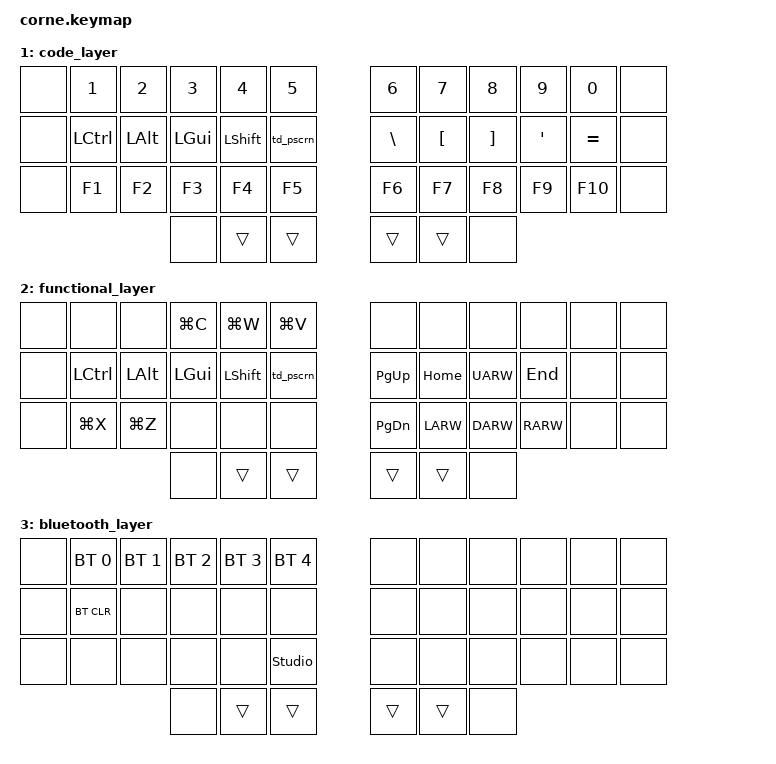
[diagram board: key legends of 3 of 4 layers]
/*
 * Copyright (c) 2020 The ZMK Contributors
 *
 * SPDX-License-Identifier: MIT
 */

#include <behaviors.dtsi>
#include <dt-bindings/zmk/keys.h>
#include <dt-bindings/zmk/bt.h>
#include <dt-bindings/zmk/ext_power.h>


/* flashing new u2f refer here https://github.com/superxc3/xcmkb/tree/main/list%20of%20items/list%20of%20keyboards/60percent/sofle/sofle%20zmk#part-b-flash-zmk
 * macro refer to this link https://github.com/superxc3/xcmkb/blob/main/list%20of%20guide/zmk-setup.md#zmk-macro
 * reserve
 * reserve
 */

// Layers
#define DEFAULT 0
#define CODE 	1
#define FUNC	2
#define BLE	3

// Bluetooth
#define BT1 	&bt BT_SEL 0
#define BT2 	&bt BT_SEL 1
#define BT3 	&bt BT_SEL 2
#define BT4 	&bt BT_SEL 3
#define BT5 	&bt BT_SEL 4

//========================================================
//===================== For MacOS ========================
//========================================================
// Home row mods macro
#define HRML(k1,k2,k3,k4) &bhm LCTRL k1	&bhm LALT k2  &bhm LGUI k3  &bhm LSHFT k4
#define HRMR(k1,k2,k3,k4) &bhm RSHFT k1	&bhm RGUI k2  &bhm RALT k3  &bhm RCTRL k4

// MacOS shortcuts 
#define GUI_X 			&kp LG(X)
#define GUI_Y 			&kp LG(Y)
#define GUI_W 			&kp LG(W)
#define GUI_K  			&kp LG(K)
#define GUI_C 			&kp LG(C)
#define GUI_V			&kp LG(V)
#define GUI_Z			&kp LG(Z)
#define PSCRN_COPY 		&kp LG(LS(LCTRL(4)))
#define PSCRN_SAVE 		&kp LG(LS(4))
#define SELECT_LEFT_WORD 	&kp LA(LS(LEFT)
#define SELECT_RIGHT_WORD	&kp LA(LS(RIGHT)

&caps_word {
	continue-list = <UNDERSCORE MINUS SPACE>;
};

/ {
	behaviors {
	        bhm: balanced_homerow_mods {
			compatible = "zmk,behavior-hold-tap";
			label = "HOMEROW_MODS";
			#binding-cells = <2>;
			tapping-term-ms = <200>;    // <---[[moderate duration]]
			quick-tap-ms = <125>;
			global-quick-tap;
			flavor = "balanced";
			bindings = <&kp>, <&kp>;
	        };

		td0: tap_dance_0 {
			compatible = "zmk,behavior-tap-dance";
			label = "TAP_DANCE_0";
			#binding-cells = <0>;
			tapping-term-ms = <500>;
			bindings = <&sk LSHFT>, <&caps_word>;
		};

		td_grv: tap_dance_grave_tilde {
			compatible = "zmk,behavior-tap-dance";
			label = "TAP_DANCE_GRAVE_TILDE";
			#binding-cells = <0>;
			tapping-term-ms = <500>;
			bindings = <&kp GRAVE>, <&kp TILDE>;
		};

		td_pscrn: tap_dance_pscrn {
			compatible = "zmk,behavior-tap-dance";
			label = "TAP_DANCE_PSCRN";
			#binding-cells = <0>;
			tapping-term-ms = <500>;
			bindings = <&kp LG(LS(LC(N4)))>, <&kp LG(LS(N4))>;
		};
    	};

	combos {
			compatible = "zmk,combos";

			combo_bluetooth {
				timeout-ms = <100>;
				key-positions = <39 40>;
				bindings = <&mo BLE>;
			};

			combo_grave {
				timeout-ms = <35>;
				key-positions = <1 2>;
				bindings = <&td_grv>;
				layers = <0>;
			};

			combo_esc {
				timeout-ms = <35>;
				key-positions = <2 3>;
				bindings = <&kp ESC>;
				layers = <0>;
			};

			combo_backspace {
				timeout-ms = <50>;
				key-positions = <14 15>;
				bindings = <&kp BSPC>;
				layers = <0>;
			};

			combo_delete {
				timeout-ms = <50>;
				key-positions = <15 16>;
				bindings = <&kp DEL>;
				layers = <0>;
			};

			combo_left_parenthesis {
				timeout-ms = <35>;
				key-positions = <7 8>;
				bindings = <&kp LPAR>;
				layers = <0>;
			};

			combo_right_parenthesis {
				timeout-ms = <35>;
				key-positions = <8 9>;
				bindings = <&kp RPAR>;
				layers = <0>;
			};

			combo_semicolon {
				timeout-ms = <35>;
				key-positions = <19 20>;
				bindings = <&kp SEMI>;
				layers = <0>;
			};

			combo_enter {
				timeout-ms = <50>;
				key-positions = <20 21>;
				bindings = <&kp ENTER>;
				layers = <0>;
			};

			combo_sk_lgui {
				timeout-ms = <50>;
				key-positions = <26 27>;
				bindings = <&sk LGUI>;
				layers = <0>;
			};

			combo_f11 {
				timeout-ms = <50>;
				key-positions = <32 33>;
				bindings = <&kp F11>;
				layers = <1>;
			};

			combo_f12 {
				timeout-ms = <50>;
				key-positions = <33 34>;
				bindings = <&kp F12>;
				layers = <1>;
			};
	};

        keymap {
                compatible = "zmk,keymap";

		// key-positions start from 0.

                default_layer {
                        bindings  = <
			//╭─1────────┬─2────────┬─3────────┬─4────────┬─5────────┬─6────────╮   ╭─7────────┬─8────────┬─9────────┬─10───────┬─11───────┬─12───────╮
			    &none      &kp B      &kp L	      &kp C	 &kp W	   &kp V	  &kp Q	      &kp F	 &kp O	    &kp U     &kp MINUS  &none
			//|─13───────┬─14───────┬─15───────┬─16───────┬─17───────┬─18──-────╮   ╭─19───────┬─20───────┬─21───────┬─22───────┬─23───────┬-24───-───┤
			    &none      HRML(N,	   R,	      S,	 T)	   &kp G	  &kp Y	  HRMR(H,	 E,	    I,	      A)         &none
			//|─25───────┬─26───────┬─27───────┬─28───────┬─29───────┬─30──-────╮   ╭─31───────┬─32───────┬─33───────┬─34───────┬─35───────┬-36───-───┤
			    &none       &kp X      &kp Z      &kp K	 &kp M	   &kp J	  &kp P	      &kp D     &kp COMMA   &kp DOT   &kp FSLH   &none
			//╰──────────┴──────────┴─--───────┼─37───────┼─38───────┼─39───────┤   ├─40───────┼─41───────┼─42───────┼─--───────┼─---──────┴──────────╯
			                                     &none	   &mo CODE  &lt FUNC TAB  &lt BLE SPACE  &td0       &none
			//			                       ╰──────────┴──────────┴──────────╯   ╰──────────┴──────────┴──────────╯
			>;
                };

                code_layer {
                        bindings = <
			//╭─1────────┬─2────────┬─3────────┬─4────────┬─5────────┬─6────────╮   ╭─7────────┬─8────────┬─9────────┬─10───────┬─11───────┬─12───────╮
			//│  	     │	1	    │  2	   │  3	      │	 4	     │ 5        │	| 6	       │  7	      │  8	     │  9       │  0       │          |
			    &none      &kp N1     &kp N2      &kp N3     &kp N4	   &kp N5	  &kp N6      &kp N7     &kp N8	    &kp N9     &kp N0    &none
			//|─13───────┬─14───────┬─15───────┬─16───────┬─17───────┬─18──-────╮   ╭─19───────┬─20───────┬─21───────┬─22───────┬─23───────┬-24───-───┤
			//│  	     │	LCTRL	│  LALT	   │  LGUI    │	 LSHFT	 │ PRTSCN   │	│    \ |   │  [ {     │  ] }     │ ' "      │  = +     │          |
			    &none      &kp LCTRL   &kp LALT   &kp LGUI  &kp LSHFT &td_pscrn       &kp BSLH   &kp LBKT   &kp RBKT   &kp SQT   &kp EQUAL   &none
			//|─25───────┬─26───────┬─27───────┬─28───────┬─29───────┬─30──-────╮   ╭─31───────┬─32───────┬─33───────┬─34───────┬─35───────┬-36───-───┤
			//│  	     │  F1      │  F2	   │  F3      │  F4      │  F5	    │   │   F6	   │  F7      │  F8      | F9	    │  F10     │          |
			    &none       &kp F1     &kp F2     &kp F3     &kp F4     &kp F5         &kp F6    &kp F7     &kp F8     &kp F9      &kp F10   &none
			//╰──────────┴──────────┴─--───────┼─37───────┼─38───────┼─39───────┤   ├─40───────┼─41───────┼─42───────┼─--───────┼─---──────┴──────────╯
						                          &none      &trans	    &trans	      &trans     &trans     &none
			//			                       ╰──────────┴──────────┴──────────╯   ╰──────────┴──────────┴──────────╯
			>;
		};

                functional_layer {
			bindings = <
			//╭─1────────┬─2────────┬─3────────┬─4────────┬─5────────┬─6────────╮   ╭─7────────┬─8────────┬─9────────┬─10───────┬─11───────┬─12───────╮
			    &none      &none      &none       GUI_C      GUI_W	   GUI_V	  &none      &none      &none	   &none      &none      &none
			//|─13───────┬─14───────┬─15───────┬─16───────┬─17───────┬─18──-────╮   ╭─19───────┬─20───────┬─21───────┬─22───────┬─23───────┬-24───-───┤   |
			    &none      &kp LCTRL  &kp LALT    &kp LGUI  &kp LSHFT  &td_pscrn      &kp PG_UP  &kp HOME   &kp UARW    &kp END    &none     &none 
			//|─25───────┬─26───────┬─27───────┬─28───────┬─29───────┬─30──-────╮   ╭─31───────┬─32───────┬─33───────┬─34───────┬─35───────┬-36───-───┤    |
			    &none      GUI_X      GUI_Z       &none     &none      &none         &kp PG_DN  &kp LARW   &kp DARW   &kp RARW   &none       &none
			//╰──────────┴──────────┴─--───────┼─37───────┼─38───────┼─39───────┤   ├─40───────┼─41───────┼─42───────┼─--───────┼─---──────┴──────────╯
						                          &none      &trans	    &trans	       &trans    &trans     &none
			//			                       ╰──────────┴──────────┴──────────╯   ╰──────────┴──────────┴──────────╯
			>;
		};

		bluetooth_layer {
			bindings = <
			//╭─1────────┬─2────────┬─3────────┬─4────────┬─5────────┬─6────────╮   ╭─7────────┬─8────────┬─9────────┬─10───────┬─11───────┬─12───────╮
			//│  	     │ BT #1    │  BT #2   │  BT #3   │ BT #4    │ BT #5    │   │          |	      │  	 │	    │  	       |          |
			    &none      BT1         BT2	      BT3       BT4	   BT5             &none      &none      &none	   &none      &none      &none
			//|─13───────┬─14───────┬─15───────┬─16───────┬─17───────┬─18──-────╮   ╭─19───────┬─20───────┬─21───────┬─22───────┬─23───────┬-24───-───┤
			//│  	     │ BT CLR   │  	       │          │	 	     │          │	│  	   │          │	 	 │          │          |          |
			    &none     &bt BT_CLR &none	     &none      &none	   &none          &none	      &none      &none	   &none      &none      &none
			//|─25───────┬─26───────┬─27───────┬─28───────┬─29───────┬─30──-────╮   ╭─31───────┬─32───────┬─33───────┬─34───────┬─35───────┬-36───-───┤
			//│  	     │          │ 	       │          │          │          │   │          │          │          │          │          │          |
			    &none      &none      &none      &none      &none	 &studio_unlock	  &none       &none	 &none     &none      &none	 &none
			//╰──────────┴──────────┴─--───────┼─37───────┼─38───────┼─39───────┤   ├─40───────┼─41───────┼─42───────┼─--───────┼─---──────┴──────────╯
						                          &none      &trans	    &trans	        &trans    &trans     &none
			//			                       ╰──────────┴──────────┴──────────╯   ╰──────────┴──────────┴──────────╯
			>;
		};
	};
};
